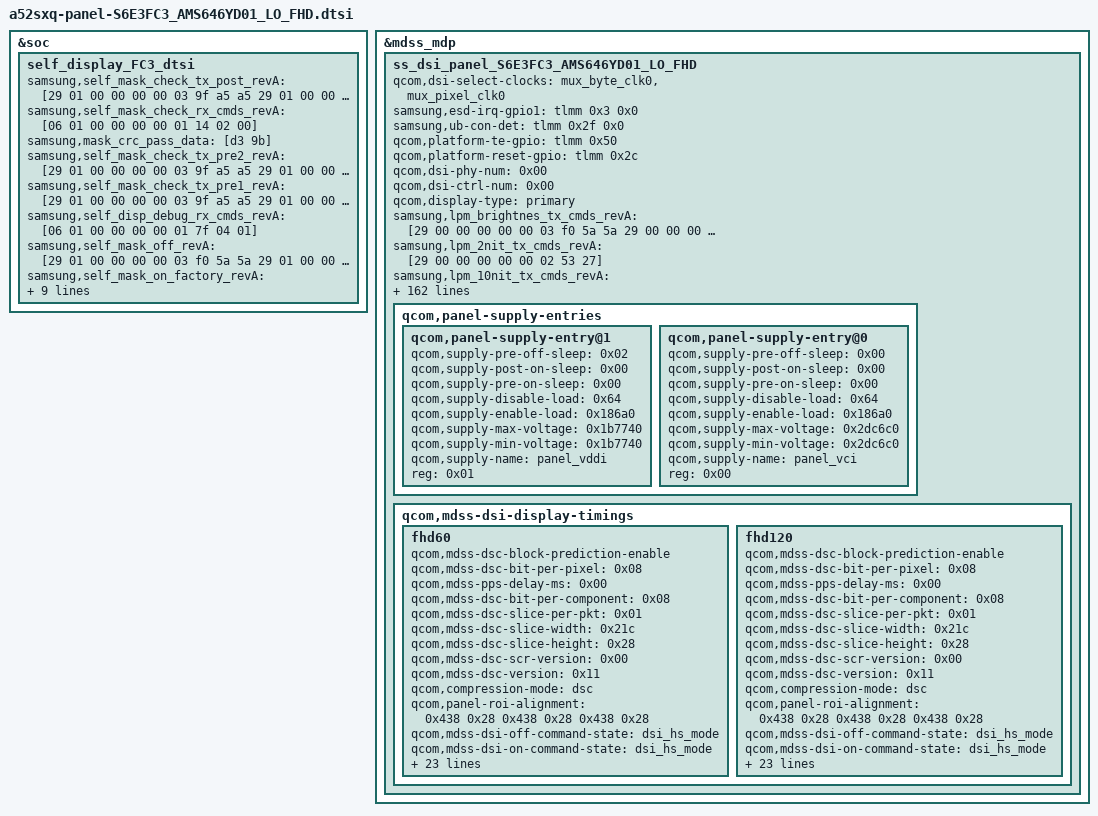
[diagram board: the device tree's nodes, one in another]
// SPDX-License-Identifier: GPL-2.0-only
/*
 * Samsung S6E3FC3 / AMS646YD01 panel node + its self-display (self mask) table.
 * GENERATED by tools/gen-dts.py from downstream-dt/a52sxq-r02.dts (the merged tree the
 * phone boots: yupik.dtb + overlay a52sxq_kor_single_w00_r02, used by hardware revisions
 * 2 and later, so 3 and 4 too). Values are byte-for-byte the phone's; only phandles were
 * turned into labels. Do not edit by hand; edit the generator.
 */

&soc {
	self_display_FC3_dtsi: self_display_FC3_dtsi {
		samsung,self_mask_check_tx_post_revA = [29 01 00 00 00 00 03 9f a5 a5 29 01 00 00 00 00 03 f0 5a 5a 29 01 00 00 00 00 03 fc 5a 5a 29 01 00 00 00 00 1a 7a 01 06 00 00 00 00 00 00 00 00 00 00 09 60 09 61 09 62 09 63 00 00 00 00 00 29 01 00 00 00 00 02 bf 00 29 01 00 00 00 00 03 fc a5 a5 29 01 00 00 00 00 03 f0 a5 a5 29 01 00 00 00 00 03 9f 5a 5a];
		samsung,self_mask_check_rx_cmds_revA = [06 01 00 00 00 00 01 14 02 00];
		samsung,mask_crc_pass_data = [d3 9b];
		samsung,self_mask_check_tx_pre2_revA = [29 01 00 00 00 00 03 9f a5 a5 29 01 00 00 00 00 03 f0 5a 5a 29 01 00 00 00 00 03 fc 5a 5a 29 01 00 00 00 00 02 75 00 29 01 00 00 22 00 1a 7a 01 06 00 00 00 00 00 00 00 00 00 00 01 f4 02 33 09 60 09 61 00 00 ff ff ff 29 01 00 00 00 00 03 fc a5 a5 29 01 00 00 00 00 03 f0 a5 a5 29 01 00 00 00 00 03 9f 5a 5a];
		samsung,self_mask_check_tx_pre1_revA = [29 01 00 00 00 00 03 9f a5 a5 29 01 00 00 00 00 03 f0 5a 5a 29 01 00 00 00 00 03 fc 5a 5a 29 01 00 00 00 00 04 b0 00 27 d8 29 01 00 00 00 00 02 d8 16 29 01 00 00 00 00 0a bf 01 07 00 00 00 10 00 00 00 29 01 00 00 11 00 02 7a 00 29 01 00 00 00 00 02 75 10 29 01 00 00 00 00 03 fc a5 a5 29 01 00 00 00 00 03 f0 a5 a5 29 01 00 00 00 00 03 9f 5a 5a];
		samsung,self_disp_debug_rx_cmds_revA = [06 01 00 00 00 00 01 7f 04 01];
		samsung,self_mask_off_revA = [29 01 00 00 00 00 03 f0 5a 5a 29 01 00 00 00 00 02 7a 00 29 01 00 00 00 00 03 f0 a5 a5];
		samsung,self_mask_on_factory_revA = [29 01 00 00 00 00 03 f0 5a 5a 29 01 00 00 00 00 17 7a 01 06 00 00 00 00 00 00 00 00 00 00 09 60 09 61 09 62 09 63 09 0c 29 01 00 00 00 00 03 f0 a5 a5];
		samsung,self_mask_on_revA = [29 01 00 00 00 00 03 f0 5a 5a 29 01 00 00 00 00 17 7a 01 06 00 00 00 00 00 00 00 00 00 00 00 00 00 95 07 9e 09 5f 09 0c 29 01 00 00 00 00 03 f0 a5 a5];
		samsung,self_mask_setting_post_revA = [29 01 00 00 00 00 02 75 00];
		samsung,self_mask_setting_pre_revA = [29 01 00 00 00 00 04 b0 00 10 f2 29 01 00 00 00 00 03 f2 26 f0 29 01 00 00 00 00 02 7a 00 29 01 00 00 00 00 02 75 10];
		samsung,support_self_display;
		label = "self_display_FC3_dtsi";
	};
};

&mdss_mdp {
	ss_dsi_panel_S6E3FC3_AMS646YD01_LO_FHD: ss_dsi_panel_S6E3FC3_AMS646YD01_LO_FHD {
		qcom,dsi-select-clocks = "mux_byte_clk0", "mux_pixel_clk0";
		samsung,esd-irq-gpio1 = <&tlmm 0x3 0x0>;
		samsung,ub-con-det = <&tlmm 0x2f 0x0>;
		qcom,platform-te-gpio = <&tlmm 0x50 0x0>;
		qcom,platform-reset-gpio = <&tlmm 0x2c 0x0>;
		qcom,dsi-phy-num = <0x00>;
		qcom,dsi-ctrl-num = <0x00>;
		qcom,display-type = "primary";
		samsung,lpm_brightnes_tx_cmds_revA = [29 00 00 00 00 00 03 f0 5a 5a 29 00 00 00 00 00 02 53 26 29 00 00 00 00 00 02 f7 0f 29 01 00 00 00 00 03 f0 a5 a5];
		samsung,lpm_2nit_tx_cmds_revA = [29 00 00 00 00 00 02 53 27];
		samsung,lpm_10nit_tx_cmds_revA = [29 00 00 00 00 00 02 53 26];
		samsung,lpm_30nit_tx_cmds_revA = [29 00 00 00 00 00 02 53 25];
		samsung,lpm_60nit_tx_cmds_revA = [29 00 00 00 00 00 02 53 24];
		samsung,lpm_off_tx_cmds_revA = [29 00 00 00 00 00 03 f0 5a 5a 29 00 00 00 00 00 04 b0 00 07 b5 29 00 00 00 00 00 04 b5 00 00 00 29 00 00 00 00 00 03 91 02 01 29 00 00 00 00 00 02 f7 0f 29 01 00 00 00 00 03 f0 a5 a5];
		samsung,lpm_off_tx_cmds_revI = [29 00 00 00 00 00 03 f0 5a 5a 29 00 00 00 00 00 04 b0 00 07 b5 29 00 00 00 00 00 04 b5 00 00 00 29 00 00 00 00 00 04 b0 01 88 cb 29 00 00 00 00 00 08 cb 45 0a 00 00 00 00 45 29 00 00 00 00 00 04 b0 01 c0 cb 29 00 00 00 00 00 08 cb 3d 00 00 00 18 03 3d 29 00 00 00 00 00 04 b0 00 10 f2 29 00 00 00 00 00 03 f2 26 f0 29 00 00 00 00 00 03 91 02 01 29 00 00 00 00 00 02 53 20 29 00 00 00 00 00 02 f7 0f 29 01 00 00 00 00 03 f0 a5 a5];
		samsung,lpm_on_tx_cmds_revA = <0x29000000 0x3f0 0x5a5a2900 0x00 0x3910101 0x29010000 0x253 0x26290000 0x02 0xf70f2901 0x00 0x3f0a5a5>;
		samsung,lpm_on_tx_cmds_revI = [29 00 00 00 00 00 03 f0 5a 5a 29 00 00 00 00 00 04 b0 00 4c f4 29 00 00 00 00 00 02 f4 28 29 00 00 00 00 00 03 91 01 01 29 00 00 00 00 00 02 53 27 29 00 00 00 00 00 04 b0 01 88 cb 29 00 00 00 00 00 08 cb 40 0a 00 00 00 00 40 29 00 00 00 00 00 04 b0 01 c0 cb 29 00 00 00 00 00 08 cb 38 00 00 00 18 03 38 29 00 00 00 00 00 04 b0 00 10 f2 29 00 00 00 00 00 03 f2 24 a4 29 01 00 00 00 00 02 f7 0f 29 01 00 00 00 00 03 f0 a5 a5];
		samsung,self_grid_off_revA = [29 01 00 00 11 00 03 f0 5a 5a 29 00 00 00 00 00 03 bf 00 00 29 01 00 00 00 00 03 f0 a5 a5];
		samsung,self_grid_on_revA = [29 00 00 00 00 00 03 f0 5a 5a 29 00 00 00 00 00 03 bf 01 00 29 01 00 00 11 00 03 f0 a5 a5];
		samsung,fd_off_tx_cmds_revA = [29 00 00 00 00 00 03 f0 5a 5a 29 00 00 00 00 00 04 b0 00 0a b5 29 00 00 00 00 00 03 b5 80 40 29 01 00 00 00 00 03 f0 a5 a5];
		samsung,fd_on_tx_cmds_revA = [29 00 00 00 00 00 03 f0 5a 5a 29 00 00 00 00 00 04 b0 00 0a b5 29 00 00 00 00 00 03 b5 40 40 29 01 00 00 00 00 03 f0 a5 a5];
		samsung,dynamic_mipi_clk_sel_table = <0x01 0x01 0x00 0x00 0x00 0x01 0x02 0x00 0x00 0x01 0x01 0x03 0x00 0x00 0x00 0x01 0x04 0x00 0x00 0x00 0x02 0x0b 0x2942 0x2a56 0x00 0x02 0x0c 0x25be 0x261a 0x01 0x02 0x0c 0x261b 0x26d2 0x00 0x02 0x0d 0x48a 0x4a3 0x01 0x02 0x0d 0x4a4 0x5e9 0x00 0x02 0x0e 0x601 0x6ca 0x00 0x02 0x0f 0x1105 0x116a 0x00 0x02 0x11 0x8bd 0x926 0x01 0x02 0x11 0x927 0xa03 0x00 0x02 0x12 0xb79 0xc0f 0x00 0x02 0x12 0xc10 0xc10 0x01 0x03 0x5b 0x00 0x257 0x00 0x03 0x5c 0x258 0x329 0x01 0x03 0x5c 0x32a 0x4af 0x00 0x03 0x5d 0x4b0 0x4fa 0x01 0x03 0x5d 0x4fb 0x79d 0x00 0x03 0x5e 0x79e 0x95f 0x00 0x03 0x5f 0x960 0xa59 0x00 0x03 0x61 0xabe 0xba8 0x01 0x03 0x61 0xba9 0xd79 0x00 0x03 0x62 0xd7a 0xebe 0x00 0x03 0x62 0xebf 0xed7 0x01 0x03 0x66 0x1392 0x143b 0x00 0x03 0x67 0x143c 0x149f 0x00 0x03 0x68 0x14a0 0x1503 0x00 0x03 0x6b 0x1662 0x16d9 0x00 0x03 0x6c 0x16da 0x176f 0x00 0x03 0x6d 0x1770 0x1805 0x00 0x03 0x6e 0x1806 0x191d 0x00 0x03 0x6e 0x191e 0x1931 0x01 0x03 0x6f 0x1932 0x19c7 0x00 0x03 0x73 0x1f68 0x2039 0x01 0x03 0x73 0x203a 0x21f1 0x00 0x03 0x74 0x21f2 0x234f 0x00 0x03 0x76 0x23fa 0x25bb 0x00 0x03 0x77 0x25bc 0x2629 0x00 0x03 0x78 0x262a 0x268d 0x01 0x03 0x7a 0x26c0 0x2877 0x00 0x03 0x7c 0x8d68 0x8dfd 0x00 0x03 0x80 0x9376 0x9564 0x00 0x03 0x80 0x9565 0x9569 0x01 0x03 0x81 0x956a 0x96f9 0x00 0x03 0x82 0x96fa 0x98a2 0x00 0x03 0x82 0x98a3 0x9992 0x01 0x03 0x82 0x9993 0x9ae1 0x00 0x03 0x83 0x9ae2 0x9b3b 0x01 0x03 0x83 0x9b3c 0x9fb4 0x00 0x03 0x83 0x9fb5 0xa0a4 0x01 0x03 0x83 0xa0a5 0xa275 0x00 0x03 0x84 0xa276 0xa46f 0x00 0x03 0x84 0xa470 0xa55f 0x01 0x03 0x84 0xa560 0xa9d8 0x00 0x03 0x84 0xa9d9 0xaa45 0x01 0x03 0x8a 0xd7c8 0xd94e 0x00 0x03 0x8a 0xd94f 0xda3e 0x01 0x03 0x8a 0xda3f 0xdda3 0x00 0x03 0x9c 0x10384 0x10707 0x00 0x03 0xa1 0x10bea 0x10d47 0x00 0x04 0x33 0x00 0x00 0x00 0x04 0x34 0x00 0x00 0x00 0x04 0x35 0x00 0x00 0x01 0x04 0x36 0x00 0x00 0x01 0x04 0x37 0x00 0x00 0x02 0x04 0x38 0x00 0x00 0x00 0x05 0x3d 0x00 0x00 0x00 0x05 0x3e 0x00 0x00 0x00 0x05 0x47 0x00 0x00 0x00 0x07 0x104 0x2a6e8 0x2ba5c 0x00 0x07 0x107 0x2d2a8 0x2e1d0 0x00 0x07 0x107 0x2e1d1 0x2ecc0 0x01 0x07 0x107 0x2ecc1 0x2edec 0x02 0x07 0x11b 0x25030 0x27344 0x00 0x07 0x146 0x1e208 0x1fd4c 0x00>;
		samsung,dynamic_mipi_clk_timing_table = <0x420abd00 0x42fee100 0x430e2340>;
		samsung,dyn_mipi_clk_ffc_cmds_revA = <0x29000000 0x4b0 0x2ac529 0x00 0x5c50d 0x10804529 0x00 0x4b000 0x2ec52900 0x00 0x3c553c7 0x29000000 0x4b0 0x2ac529 0x00 0x5c50d 0x10804529 0x00 0x4b000 0x2ec52900 0x00 0x3c55296 0x29000000 0x4b0 0x2ac529 0x00 0x5c50d 0x10804529 0x00 0x4b000 0x2ec52900 0x00 0x3c55283>;
		samsung,ffc_tx_cmds_revA = [29 00 00 00 00 00 03 f0 5a 5a 29 00 00 00 00 00 03 fc 5a 5a 29 00 00 00 00 00 04 b0 00 2a c5 29 00 00 00 00 00 05 c5 0d 10 80 45 29 00 00 00 00 00 04 b0 00 2e c5 29 00 00 00 00 00 03 c5 53 c7 29 00 00 00 00 00 02 f7 0f 29 00 00 00 00 00 03 fc a5 a5 29 00 00 00 00 00 03 f0 a5 a5];
		samsung,support_dynamic_mipi_clk;
		samsung,hmt_disable_tx_cmds_revA = [29 00 00 00 00 00 03 f0 5a 5a 29 00 00 00 00 00 04 b0 00 0b cb 29 00 00 00 00 00 02 cb 11 29 00 00 00 00 00 04 b0 00 1f cb 29 00 00 00 00 00 02 cb 11 29 00 00 00 00 00 04 b0 00 39 cb 29 00 00 00 00 00 02 cb 7f 29 00 00 00 00 00 04 b0 00 60 cb 29 00 00 00 00 00 02 cb 06 29 00 00 00 00 00 04 b0 00 ab cb 29 00 00 00 00 00 02 cb 00 29 00 00 00 00 00 04 b0 00 e0 cb 29 00 00 00 00 00 02 cb 06 29 00 00 00 00 00 04 b0 01 2b cb 29 00 00 00 00 00 02 cb 00 29 00 00 00 00 00 04 b0 01 ab cb 29 00 00 00 00 00 02 cb 00 29 00 00 00 00 00 04 b0 00 06 f2 29 00 00 00 00 00 02 f2 0c 29 00 00 00 00 00 04 b0 02 2c 65 29 00 00 00 00 00 02 65 11 29 00 00 00 00 00 04 b0 01 d4 65 29 00 00 00 00 00 03 65 09 70 29 00 00 00 00 00 04 b0 01 ee 65 29 00 00 00 00 00 05 65 01 84 01 84 29 00 00 00 0a 00 02 f7 0f 29 00 00 00 00 00 03 f0 a5 a5];
		samsung,hmt_enable_tx_cmds_revA = [29 00 00 00 00 00 03 f0 5a 5a 29 00 00 00 00 00 03 60 00 00 29 00 00 00 00 00 04 b0 00 28 68 29 00 00 00 00 00 02 68 22 29 00 00 00 00 00 04 b0 00 0d f2 29 00 00 00 00 00 02 f2 14 29 00 00 00 00 00 04 b0 02 2c 65 29 00 00 00 00 00 02 65 10 29 00 00 00 00 00 04 b0 01 d4 65 29 00 00 00 00 00 03 65 12 d8 29 00 00 00 00 00 04 b0 01 ee 65 29 00 00 00 00 00 05 65 0f 6a 0f 6a 29 00 00 00 11 00 02 f7 0f 29 00 00 00 00 00 04 b0 00 0b cb 29 00 00 00 00 00 02 cb 12 29 00 00 00 00 00 04 b0 00 1f cb 29 00 00 00 00 00 02 cb 12 29 00 00 00 00 00 04 b0 00 39 cb 29 00 00 00 00 00 02 cb bf 29 00 00 00 00 00 04 b0 00 60 cb 29 00 00 00 00 00 02 cb 0e 29 00 00 00 00 00 04 b0 00 ab cb 29 00 00 00 00 00 02 cb 17 29 00 00 00 00 00 04 b0 00 e0 cb 29 00 00 00 00 00 02 cb 0e 29 00 00 00 00 00 04 b0 01 2b cb 29 00 00 00 00 00 02 cb 17 29 00 00 00 00 00 04 b0 01 ab cb 29 00 00 00 00 00 02 cb 17 29 00 00 00 0a 00 02 f7 0f 29 00 00 00 00 00 03 51 03 ff 29 00 00 00 00 00 03 f0 a5 a5];
		samsung,gamma_mode2_hmt_tx_cmds_revA = [29 00 00 00 00 00 03 51 03 ff 29 00 00 00 00 00 02 f7 0f];
		samsung,hmt_candela_map_table_revA = <0x00 0x00 0x00 0x10c 0x14 0x01 0x01 0x01 0x10f 0x14 0x02 0x02 0x02 0x112 0x15 0x03 0x03 0x03 0x115 0x15 0x04 0x04 0x04 0x118 0x15 0x05 0x05 0x05 0x11b 0x16 0x06 0x06 0x06 0x11e 0x16 0x07 0x07 0x07 0x121 0x16 0x08 0x08 0x08 0x124 0x17 0x09 0x09 0x09 0x127 0x17 0x0a 0x0a 0x0a 0x12a 0x17 0x0b 0x0b 0x0b 0x12d 0x18 0x0c 0x0c 0x0c 0x130 0x18 0x0d 0x0d 0x0d 0x132 0x18 0x0e 0x0e 0x0e 0x135 0x19 0x0f 0x0f 0x0f 0x138 0x19 0x10 0x10 0x10 0x13b 0x19 0x11 0x11 0x11 0x13e 0x1a 0x12 0x12 0x12 0x141 0x1a 0x13 0x13 0x13 0x144 0x1a 0x14 0x14 0x14 0x147 0x1b 0x15 0x15 0x15 0x14a 0x1b 0x16 0x16 0x16 0x14d 0x1b 0x17 0x17 0x17 0x150 0x1c 0x18 0x18 0x18 0x153 0x1c 0x19 0x19 0x19 0x156 0x1c 0x1a 0x1a 0x1a 0x159 0x1d 0x1b 0x1b 0x1b 0x15c 0x1d 0x1c 0x1c 0x1c 0x15f 0x1d 0x1d 0x1d 0x1d 0x162 0x1e 0x1e 0x1e 0x1e 0x165 0x1e 0x1f 0x1f 0x1f 0x168 0x1e 0x20 0x20 0x20 0x16b 0x1f 0x21 0x21 0x21 0x16e 0x1f 0x22 0x22 0x22 0x171 0x1f 0x23 0x23 0x23 0x174 0x20 0x24 0x24 0x24 0x177 0x20 0x25 0x25 0x25 0x17a 0x20 0x26 0x26 0x26 0x17c 0x21 0x27 0x27 0x27 0x17f 0x21 0x28 0x28 0x28 0x182 0x21 0x29 0x29 0x29 0x185 0x22 0x2a 0x2a 0x2a 0x188 0x22 0x2b 0x2b 0x2b 0x18b 0x22 0x2c 0x2c 0x2c 0x18e 0x23 0x2d 0x2d 0x2d 0x191 0x23 0x2e 0x2e 0x2e 0x194 0x23 0x2f 0x2f 0x2f 0x197 0x24 0x30 0x30 0x30 0x19a 0x24 0x31 0x31 0x31 0x19d 0x24 0x32 0x32 0x32 0x1a0 0x25 0x33 0x33 0x33 0x1a3 0x25 0x34 0x34 0x34 0x1a6 0x25 0x35 0x35 0x35 0x1a9 0x26 0x36 0x36 0x36 0x1ac 0x26 0x37 0x37 0x37 0x1af 0x26 0x38 0x38 0x38 0x1b2 0x27 0x39 0x39 0x39 0x1b5 0x27 0x3a 0x3a 0x3a 0x1b8 0x27 0x3b 0x3b 0x3b 0x1bb 0x28 0x3c 0x3c 0x3c 0x1be 0x28 0x3d 0x3d 0x3d 0x1c1 0x28 0x3e 0x3e 0x3e 0x1c4 0x29 0x3f 0x3f 0x3f 0x1c7 0x29 0x40 0x40 0x40 0x1c9 0x29 0x41 0x41 0x41 0x1cc 0x2a 0x42 0x42 0x42 0x1cf 0x2a 0x43 0x43 0x43 0x1d2 0x2a 0x44 0x44 0x44 0x1d5 0x2b 0x45 0x45 0x45 0x1d8 0x2b 0x46 0x46 0x46 0x1db 0x2b 0x47 0x47 0x47 0x1de 0x2c 0x48 0x48 0x48 0x1e1 0x2c 0x49 0x49 0x49 0x1e4 0x2c 0x4a 0x4a 0x4a 0x1e7 0x2d 0x4b 0x4b 0x4b 0x1ea 0x2d 0x4c 0x4c 0x4c 0x1ed 0x2d 0x4d 0x4d 0x4d 0x1f0 0x2e 0x4e 0x4e 0x4e 0x1f3 0x2e 0x4f 0x4f 0x4f 0x1f6 0x2e 0x50 0x50 0x50 0x1f9 0x2f 0x51 0x51 0x51 0x1fc 0x2f 0x52 0x52 0x52 0x1ff 0x2f 0x53 0x53 0x53 0x202 0x30 0x54 0x54 0x54 0x205 0x30 0x55 0x55 0x55 0x208 0x30 0x56 0x56 0x56 0x20b 0x31 0x57 0x57 0x57 0x20e 0x31 0x58 0x58 0x58 0x211 0x31 0x59 0x59 0x59 0x213 0x32 0x5a 0x5a 0x5a 0x216 0x32 0x5b 0x5b 0x5b 0x219 0x32 0x5c 0x5c 0x5c 0x21c 0x33 0x5d 0x5d 0x5d 0x21f 0x33 0x5e 0x5e 0x5e 0x222 0x33 0x5f 0x5f 0x5f 0x225 0x34 0x60 0x60 0x60 0x228 0x34 0x61 0x61 0x61 0x22b 0x34 0x62 0x62 0x62 0x22e 0x35 0x63 0x63 0x63 0x231 0x35 0x64 0x64 0x64 0x234 0x35 0x65 0x65 0x65 0x237 0x36 0x66 0x66 0x66 0x23a 0x36 0x67 0x67 0x67 0x23d 0x36 0x68 0x68 0x68 0x240 0x37 0x69 0x69 0x69 0x243 0x37 0x6a 0x6a 0x6a 0x246 0x37 0x6b 0x6b 0x6b 0x249 0x38 0x6c 0x6c 0x6c 0x24c 0x38 0x6d 0x6d 0x6d 0x24f 0x38 0x6e 0x6e 0x6e 0x252 0x39 0x6f 0x6f 0x6f 0x255 0x39 0x70 0x70 0x70 0x258 0x39 0x71 0x71 0x71 0x25b 0x3a 0x72 0x72 0x72 0x25e 0x3a 0x73 0x73 0x73 0x260 0x3a 0x74 0x74 0x74 0x263 0x3b 0x75 0x75 0x75 0x266 0x3b 0x76 0x76 0x76 0x269 0x3b 0x77 0x77 0x77 0x26c 0x3c 0x78 0x78 0x78 0x26f 0x3c 0x79 0x79 0x79 0x272 0x3c 0x7a 0x7a 0x7a 0x275 0x3d 0x7b 0x7b 0x7b 0x278 0x3d 0x7c 0x7c 0x7c 0x27b 0x3d 0x7d 0x7d 0x7d 0x27e 0x3e 0x7e 0x7e 0x7e 0x281 0x3e 0x7f 0x7f 0x7f 0x284 0x3e 0x80 0x80 0x80 0x287 0x3f 0x81 0x81 0x81 0x28a 0x3f 0x82 0x82 0x82 0x28d 0x3f 0x83 0x83 0x83 0x290 0x40 0x84 0x84 0x84 0x293 0x40 0x85 0x85 0x85 0x296 0x40 0x86 0x86 0x86 0x299 0x41 0x87 0x87 0x87 0x29c 0x41 0x88 0x88 0x88 0x29f 0x41 0x89 0x89 0x89 0x2a2 0x42 0x8a 0x8a 0x8a 0x2a5 0x42 0x8b 0x8b 0x8b 0x2a8 0x42 0x8c 0x8c 0x8c 0x2aa 0x43 0x8d 0x8d 0x8d 0x2ad 0x43 0x8e 0x8e 0x8e 0x2b0 0x43 0x8f 0x8f 0x8f 0x2b3 0x44 0x90 0x90 0x90 0x2b6 0x44 0x91 0x91 0x91 0x2b9 0x44 0x92 0x92 0x92 0x2bc 0x45 0x93 0x93 0x93 0x2bf 0x45 0x94 0x94 0x94 0x2c2 0x45 0x95 0x95 0x95 0x2c5 0x46 0x96 0x96 0x96 0x2c8 0x46 0x97 0x97 0x97 0x2cb 0x46 0x98 0x98 0x98 0x2ce 0x47 0x99 0x99 0x99 0x2d1 0x47 0x9a 0x9a 0x9a 0x2d4 0x47 0x9b 0x9b 0x9b 0x2d7 0x48 0x9c 0x9c 0x9c 0x2da 0x48 0x9d 0x9d 0x9d 0x2dd 0x48 0x9e 0x9e 0x9e 0x2e0 0x49 0x9f 0x9f 0x9f 0x2e3 0x49 0xa0 0xa0 0xa0 0x2e6 0x49 0xa1 0xa1 0xa1 0x2e9 0x4a 0xa2 0xa2 0xa2 0x2ec 0x4a 0xa3 0xa3 0xa3 0x2ef 0x4a 0xa4 0xa4 0xa4 0x2f2 0x4b 0xa5 0xa5 0xa5 0x2f5 0x4b 0xa6 0xa6 0xa6 0x2f7 0x4b 0xa7 0xa7 0xa7 0x2fa 0x4c 0xa8 0xa8 0xa8 0x2fd 0x4c 0xa9 0xa9 0xa9 0x300 0x4c 0xaa 0xaa 0xaa 0x303 0x4d 0xab 0xab 0xab 0x306 0x4d 0xac 0xac 0xac 0x309 0x4d 0xad 0xad 0xad 0x30c 0x4e 0xae 0xae 0xae 0x30f 0x4e 0xaf 0xaf 0xaf 0x312 0x4e 0xb0 0xb0 0xb0 0x315 0x4f 0xb1 0xb1 0xb1 0x318 0x4f 0xb2 0xb2 0xb2 0x31b 0x4f 0xb3 0xb3 0xb3 0x31e 0x50 0xb4 0xb4 0xb4 0x321 0x50 0xb5 0xb5 0xb5 0x324 0x50 0xb6 0xb6 0xb6 0x327 0x51 0xb7 0xb7 0xb7 0x32a 0x51 0xb8 0xb8 0xb8 0x32d 0x51 0xb9 0xb9 0xb9 0x330 0x52 0xba 0xba 0xba 0x333 0x52 0xbb 0xbb 0xbb 0x336 0x52 0xbc 0xbc 0xbc 0x339 0x53 0xbd 0xbd 0xbd 0x33c 0x53 0xbe 0xbe 0xbe 0x33f 0x53 0xbf 0xbf 0xbf 0x341 0x54 0xc0 0xc0 0xc0 0x344 0x54 0xc1 0xc1 0xc1 0x347 0x54 0xc2 0xc2 0xc2 0x34a 0x55 0xc3 0xc3 0xc3 0x34d 0x55 0xc4 0xc4 0xc4 0x350 0x55 0xc5 0xc5 0xc5 0x353 0x56 0xc6 0xc6 0xc6 0x356 0x56 0xc7 0xc7 0xc7 0x359 0x56 0xc8 0xc8 0xc8 0x35c 0x57 0xc9 0xc9 0xc9 0x35f 0x57 0xca 0xca 0xca 0x362 0x57 0xcb 0xcb 0xcb 0x365 0x58 0xcc 0xcc 0xcc 0x368 0x58 0xcd 0xcd 0xcd 0x36b 0x58 0xce 0xce 0xce 0x36e 0x59 0xcf 0xcf 0xcf 0x371 0x59 0xd0 0xd0 0xd0 0x374 0x59 0xd1 0xd1 0xd1 0x377 0x5a 0xd2 0xd2 0xd2 0x37a 0x5a 0xd3 0xd3 0xd3 0x37d 0x5a 0xd4 0xd4 0xd4 0x380 0x5b 0xd5 0xd5 0xd5 0x383 0x5b 0xd6 0xd6 0xd6 0x386 0x5b 0xd7 0xd7 0xd7 0x389 0x5c 0xd8 0xd8 0xd8 0x38c 0x5c 0xd9 0xd9 0xd9 0x38e 0x5c 0xda 0xda 0xda 0x391 0x5d 0xdb 0xdb 0xdb 0x394 0x5d 0xdc 0xdc 0xdc 0x397 0x5d 0xdd 0xdd 0xdd 0x39a 0x5e 0xde 0xde 0xde 0x39d 0x5e 0xdf 0xdf 0xdf 0x3a0 0x5e 0xe0 0xe0 0xe0 0x3a3 0x5f 0xe1 0xe1 0xe1 0x3a6 0x5f 0xe2 0xe2 0xe2 0x3a9 0x5f 0xe3 0xe3 0xe3 0x3ac 0x60 0xe4 0xe4 0xe4 0x3af 0x60 0xe5 0xe5 0xe5 0x3b2 0x60 0xe6 0xe6 0xe6 0x3b5 0x61 0xe7 0xe7 0xe7 0x3b8 0x61 0xe8 0xe8 0xe8 0x3bb 0x61 0xe9 0xe9 0xe9 0x3be 0x62 0xea 0xea 0xea 0x3c1 0x62 0xeb 0xeb 0xeb 0x3c4 0x62 0xec 0xec 0xec 0x3c7 0x63 0xed 0xed 0xed 0x3ca 0x63 0xee 0xee 0xee 0x3cd 0x63 0xef 0xef 0xef 0x3d0 0x64 0xf0 0xf0 0xf0 0x3d3 0x64 0xf1 0xf1 0xf1 0x3d6 0x64 0xf2 0xf2 0xf2 0x3d8 0x65 0xf3 0xf3 0xf3 0x3db 0x65 0xf4 0xf4 0xf4 0x3de 0x65 0xf5 0xf5 0xf5 0x3e1 0x66 0xf6 0xf6 0xf6 0x3e4 0x66 0xf7 0xf7 0xf7 0x3e7 0x66 0xf8 0xf8 0xf8 0x3ea 0x67 0xf9 0xf9 0xf9 0x3ed 0x67 0xfa 0xfa 0xfa 0x3f0 0x67 0xfb 0xfb 0xfb 0x3f3 0x68 0xfc 0xfc 0xfc 0x3f6 0x68 0xfd 0xfd 0xfd 0x3f9 0x68 0xfe 0xfe 0xfe 0x3fc 0x69 0xff 0xff 0xff 0x3ff 0x69>;
		samsung,support_hmt;
		samsung,aod_candela_map_table_revA = <0x00 0x00 0x0b 0x1b 0x02 0x01 0x0c 0x1f 0x1a 0x0a 0x02 0x20 0x36 0x19 0x1e 0x03 0x37 0xff 0x18 0x3c>;
		samsung,hbm_candela_map_table_revA = <0x00 0x100 0x100 0x00 0x1a9 0x01 0x101 0x101 0x03 0x1aa 0x02 0x102 0x102 0x06 0x1ac 0x03 0x103 0x103 0x09 0x1ae 0x04 0x104 0x104 0x0c 0x1b0 0x05 0x105 0x105 0x0f 0x1b1 0x06 0x106 0x106 0x12 0x1b3 0x07 0x107 0x107 0x15 0x1b4 0x08 0x108 0x108 0x18 0x1b6 0x09 0x109 0x109 0x1b 0x1b8 0x0a 0x10a 0x10a 0x1e 0x1b9 0x0b 0x10b 0x10b 0x21 0x1bb 0x0c 0x10c 0x10c 0x24 0x1bc 0x0d 0x10d 0x10d 0x27 0x1be 0x0e 0x10e 0x10e 0x2a 0x1c0 0x0f 0x10f 0x10f 0x2d 0x1c2 0x10 0x110 0x110 0x30 0x1c3 0x11 0x111 0x111 0x33 0x1c5 0x12 0x112 0x112 0x36 0x1c6 0x13 0x113 0x113 0x39 0x1c8 0x14 0x114 0x114 0x3c 0x1ca 0x15 0x115 0x115 0x3f 0x1cb 0x16 0x116 0x116 0x42 0x1cd 0x17 0x117 0x117 0x45 0x1ce 0x18 0x118 0x118 0x48 0x1d0 0x19 0x119 0x119 0x4b 0x1d2 0x1a 0x11a 0x11a 0x4e 0x1d4 0x1b 0x11b 0x11b 0x51 0x1d5 0x1c 0x11c 0x11c 0x54 0x1d7 0x1d 0x11d 0x11d 0x56 0x1d8 0x1e 0x11e 0x11e 0x58 0x1da 0x1f 0x11f 0x11f 0x5a 0x1dc 0x20 0x120 0x120 0x5c 0x1dd 0x21 0x121 0x121 0x5e 0x1df 0x22 0x122 0x122 0x60 0x1e0 0x23 0x123 0x123 0x62 0x1e2 0x24 0x124 0x124 0x64 0x1e4 0x25 0x125 0x125 0x66 0x1e5 0x26 0x126 0x126 0x68 0x1e7 0x27 0x127 0x127 0x6a 0x1e8 0x28 0x128 0x128 0x6c 0x1ea 0x29 0x129 0x129 0x6e 0x1ec 0x2a 0x12a 0x12a 0x70 0x1ee 0x2b 0x12b 0x12b 0x72 0x1ef 0x2c 0x12c 0x12c 0x74 0x1f1 0x2d 0x12d 0x12d 0x76 0x1f2 0x2e 0x12e 0x12e 0x78 0x1f4 0x2f 0x12f 0x12f 0x7a 0x1f6 0x30 0x130 0x130 0x7c 0x1f7 0x31 0x131 0x131 0x7e 0x1f9 0x32 0x132 0x132 0x80 0x1fa 0x33 0x133 0x133 0x82 0x1fc 0x34 0x134 0x134 0x84 0x1fe 0x35 0x135 0x135 0x86 0x200 0x36 0x136 0x136 0x88 0x201 0x37 0x137 0x137 0x8a 0x203 0x38 0x138 0x138 0x8c 0x204 0x39 0x139 0x139 0x8e 0x206 0x3a 0x13a 0x13a 0x90 0x208 0x3b 0x13b 0x13b 0x92 0x209 0x3c 0x13c 0x13c 0x94 0x20b 0x3d 0x13d 0x13d 0x96 0x20c 0x3e 0x13e 0x13e 0x98 0x20e 0x3f 0x13f 0x13f 0x9a 0x210 0x40 0x140 0x140 0x9c 0x211 0x41 0x141 0x141 0x9e 0x213 0x42 0x142 0x142 0xa0 0x215 0x43 0x143 0x143 0xa2 0x216 0x44 0x144 0x144 0xa4 0x218 0x45 0x145 0x145 0xa6 0x21a 0x46 0x146 0x146 0xa8 0x21b 0x47 0x147 0x147 0xaa 0x21d 0x48 0x148 0x148 0xac 0x21e 0x49 0x149 0x149 0xae 0x220 0x4a 0x14a 0x14a 0xb0 0x222 0x4b 0x14b 0x14b 0xb2 0x223 0x4c 0x14c 0x14c 0xb6 0x225 0x4d 0x14d 0x14d 0xba 0x226 0x4e 0x14e 0x14e 0xbe 0x228 0x4f 0x14f 0x14f 0xc2 0x22a 0x50 0x150 0x150 0xc6 0x22b 0x51 0x151 0x151 0xcb 0x22d 0x52 0x152 0x152 0xd0 0x22f 0x53 0x153 0x153 0xd5 0x230 0x54 0x154 0x154 0xda 0x232 0x55 0x155 0x155 0xdf 0x234 0x56 0x156 0x156 0xe4 0x235 0x57 0x157 0x157 0xe9 0x237 0x58 0x158 0x158 0xee 0x238 0x59 0x159 0x159 0xf3 0x23a 0x5a 0x15a 0x15a 0xf8 0x23c 0x5b 0x15b 0x15b 0xfd 0x23d 0x5c 0x15c 0x15c 0x102 0x23f 0x5d 0x15d 0x15d 0x107 0x241 0x5e 0x15e 0x15e 0x10c 0x242 0x5f 0x15f 0x15f 0x111 0x244 0x60 0x160 0x160 0x116 0x246 0x61 0x161 0x161 0x11b 0x247 0x62 0x162 0x162 0x120 0x249 0x63 0x163 0x163 0x125 0x24a 0x64 0x164 0x164 0x12a 0x24c 0x65 0x165 0x165 0x12f 0x24e 0x66 0x166 0x166 0x134 0x24f 0x67 0x167 0x167 0x139 0x251 0x68 0x168 0x168 0x13e 0x253 0x69 0x169 0x169 0x143 0x254 0x6a 0x16a 0x16a 0x148 0x256 0x6b 0x16b 0x16b 0x14d 0x257 0x6c 0x16c 0x16c 0x152 0x259 0x6d 0x16d 0x16d 0x157 0x25b 0x6e 0x16e 0x16e 0x15c 0x25c 0x6f 0x16f 0x16f 0x161 0x25e 0x70 0x170 0x170 0x166 0x260 0x71 0x171 0x171 0x16b 0x261 0x72 0x172 0x172 0x170 0x263 0x73 0x173 0x173 0x175 0x264 0x74 0x174 0x174 0x17a 0x266 0x75 0x175 0x175 0x17f 0x268 0x76 0x176 0x176 0x184 0x269 0x77 0x177 0x177 0x189 0x26b 0x78 0x178 0x178 0x18e 0x26d 0x79 0x179 0x179 0x193 0x26e 0x7a 0x17a 0x17a 0x198 0x270 0x7b 0x17b 0x17b 0x19d 0x272 0x7c 0x17c 0x17c 0x1a2 0x273 0x7d 0x17d 0x17d 0x1a7 0x275 0x7e 0x17e 0x17e 0x1ac 0x276 0x7f 0x17f 0x17f 0x1b1 0x278 0x80 0x180 0x180 0x1b6 0x27a 0x81 0x181 0x181 0x1bb 0x27b 0x82 0x182 0x182 0x1c0 0x27d 0x83 0x183 0x183 0x1c5 0x27f 0x84 0x184 0x184 0x1ca 0x280 0x85 0x185 0x185 0x1cf 0x282 0x86 0x186 0x186 0x1d4 0x283 0x87 0x187 0x187 0x1d9 0x285 0x88 0x188 0x188 0x1de 0x287 0x89 0x189 0x189 0x1e3 0x288 0x8a 0x18a 0x18a 0x1e8 0x28a 0x8b 0x18b 0x18b 0x1ed 0x28c 0x8c 0x18c 0x18c 0x1f2 0x28d 0x8d 0x18d 0x18d 0x1f7 0x28f 0x8e 0x18e 0x18e 0x1fc 0x291 0x8f 0x18f 0x18f 0x201 0x292 0x90 0x190 0x190 0x206 0x294 0x91 0x191 0x191 0x20b 0x295 0x92 0x192 0x192 0x210 0x297 0x93 0x193 0x193 0x215 0x299 0x94 0x194 0x194 0x21a 0x29a 0x95 0x195 0x195 0x21f 0x29c 0x96 0x196 0x196 0x224 0x29e 0x97 0x197 0x197 0x229 0x29f 0x98 0x198 0x198 0x22e 0x2a1 0x99 0x199 0x199 0x233 0x2a3 0x9a 0x19a 0x19a 0x238 0x2a4 0x9b 0x19b 0x19b 0x23d 0x2a6 0x9c 0x19c 0x19c 0x242 0x2a7 0x9d 0x19d 0x19d 0x247 0x2a9 0x9e 0x19e 0x19e 0x24d 0x2ab 0x9f 0x19f 0x19f 0x253 0x2ac 0xa0 0x1a0 0x1a0 0x259 0x2ae 0xa1 0x1a1 0x1a1 0x25f 0x2af 0xa2 0x1a2 0x1a2 0x265 0x2b1 0xa3 0x1a3 0x1a3 0x26b 0x2b3 0xa4 0x1a4 0x1a4 0x271 0x2b4 0xa5 0x1a5 0x1a5 0x277 0x2b6 0xa6 0x1a6 0x1a6 0x27d 0x2b8 0xa7 0x1a7 0x1a7 0x283 0x2b9 0xa8 0x1a8 0x1a8 0x289 0x2bb 0xa9 0x1a9 0x1a9 0x28f 0x2bd 0xaa 0x1aa 0x1aa 0x295 0x2be 0xab 0x1ab 0x1ab 0x29b 0x2c0 0xac 0x1ac 0x1ac 0x2a1 0x2c1 0xad 0x1ad 0x1ad 0x2a7 0x2c3 0xae 0x1ae 0x1ae 0x2ad 0x2c5 0xaf 0x1af 0x1af 0x2b3 0x2c6 0xb0 0x1b0 0x1b0 0x2b9 0x2c8 0xb1 0x1b1 0x1b1 0x2bf 0x2c9 0xb2 0x1b2 0x1b2 0x2c5 0x2cb 0xb3 0x1b3 0x1b3 0x2cb 0x2cd 0xb4 0x1b4 0x1b4 0x2d1 0x2cf 0xb5 0x1b5 0x1b5 0x2d7 0x2d0 0xb6 0x1b6 0x1b6 0x2dd 0x2d2 0xb7 0x1b7 0x1b7 0x2e3 0x2d3 0xb8 0x1b8 0x1b8 0x2e9 0x2d5 0xb9 0x1b9 0x1b9 0x2ef 0x2d7 0xba 0x1ba 0x1ba 0x2f5 0x2d8 0xbb 0x1bb 0x1bb 0x2fb 0x2da 0xbc 0x1bc 0x1bc 0x301 0x2db 0xbd 0x1bd 0x1bd 0x307 0x2dd 0xbe 0x1be 0x1be 0x30d 0x2df 0xbf 0x1bf 0x1bf 0x313 0x2e1 0xc0 0x1c0 0x1c0 0x319 0x2e2 0xc1 0x1c1 0x1c1 0x31f 0x2e4 0xc2 0x1c2 0x1c2 0x325 0x2e5 0xc3 0x1c3 0x1c3 0x32b 0x2e7 0xc4 0x1c4 0x1c4 0x331 0x2e9 0xc5 0x1c5 0x1c5 0x337 0x2ea 0xc6 0x1c6 0x1c6 0x33d 0x2ec 0xc7 0x1c7 0x1c7 0x343 0x2ed 0xc8 0x1c8 0x1c8 0x349 0x2ef 0xc9 0x1c9 0x1c9 0x34f 0x2f1 0xca 0x1ca 0x1ca 0x355 0x2f2 0xcb 0x1cb 0x1cb 0x35b 0x2f4 0xcc 0x1cc 0x1cc 0x361 0x2f5 0xcd 0x1cd 0x1cd 0x367 0x2f7 0xce 0x1ce 0x1ce 0x36d 0x2f9 0xcf 0x1cf 0x1cf 0x373 0x2fb 0xd0 0x1d0 0x1d0 0x379 0x2fc 0xd1 0x1d1 0x1d1 0x37f 0x2fe 0xd2 0x1d2 0x1d2 0x385 0x2ff 0xd3 0x1d3 0x1d3 0x38b 0x301 0xd4 0x1d4 0x1d4 0x391 0x303 0xd5 0x1d5 0x1d5 0x397 0x304 0xd6 0x1d6 0x1d6 0x39d 0x306 0xd7 0x1d7 0x1d7 0x3a3 0x307 0xd8 0x1d8 0x1d8 0x3a9 0x309 0xd9 0x1d9 0x1d9 0x3af 0x30b 0xda 0x1da 0x1da 0x3b5 0x30d 0xdb 0x1db 0x1db 0x3bb 0x30e 0xdc 0x1dc 0x1dc 0x3c1 0x310 0xdd 0x1dd 0x1dd 0x3c7 0x311 0xde 0x1de 0x1de 0x3cd 0x313 0xdf 0x1df 0x1df 0x3d3 0x315 0xe0 0x1e0 0x1e0 0x3d9 0x316 0xe1 0x1e1 0x1e1 0x3df 0x318 0xe2 0x1e2 0x1e2 0x3e5 0x319 0xe3 0x1e3 0x1e3 0x3eb 0x31b 0xe4 0x1e4 0x1e4 0x3f1 0x31d 0xe5 0x1e5 0x1e5 0x3f7 0x31f 0xe6 0x1e6 0x1e6 0x3ff 0x320>;
		samsung,hbm_candela_map_table_revI = <0x00 0x100 0x100 0x00 0x1a9 0x01 0x101 0x101 0x02 0x1aa 0x02 0x102 0x102 0x04 0x1ac 0x03 0x103 0x103 0x06 0x1ae 0x04 0x104 0x104 0x08 0x1b0 0x05 0x105 0x105 0x0a 0x1b1 0x06 0x106 0x106 0x0c 0x1b3 0x07 0x107 0x107 0x0e 0x1b4 0x08 0x108 0x108 0x10 0x1b6 0x09 0x109 0x109 0x12 0x1b8 0x0a 0x10a 0x10a 0x14 0x1b9 0x0b 0x10b 0x10b 0x16 0x1bb 0x0c 0x10c 0x10c 0x18 0x1bc 0x0d 0x10d 0x10d 0x1a 0x1be 0x0e 0x10e 0x10e 0x1c 0x1c0 0x0f 0x10f 0x10f 0x1e 0x1c2 0x10 0x110 0x110 0x20 0x1c3 0x11 0x111 0x111 0x22 0x1c5 0x12 0x112 0x112 0x24 0x1c6 0x13 0x113 0x113 0x25 0x1c8 0x14 0x114 0x114 0x26 0x1ca 0x15 0x115 0x115 0x27 0x1cb 0x16 0x116 0x116 0x28 0x1cd 0x17 0x117 0x117 0x29 0x1ce 0x18 0x118 0x118 0x2a 0x1d0 0x19 0x119 0x119 0x2b 0x1d2 0x1a 0x11a 0x11a 0x2c 0x1d4 0x1b 0x11b 0x11b 0x2d 0x1d5 0x1c 0x11c 0x11c 0x2e 0x1d7 0x1d 0x11d 0x11d 0x2f 0x1d8 0x1e 0x11e 0x11e 0x30 0x1da 0x1f 0x11f 0x11f 0x31 0x1dc 0x20 0x120 0x120 0x32 0x1dd 0x21 0x121 0x121 0x33 0x1df 0x22 0x122 0x122 0x34 0x1e0 0x23 0x123 0x123 0x35 0x1e2 0x24 0x124 0x124 0x36 0x1e4 0x25 0x125 0x125 0x37 0x1e5 0x26 0x126 0x126 0x38 0x1e7 0x27 0x127 0x127 0x39 0x1e8 0x28 0x128 0x128 0x3a 0x1ea 0x29 0x129 0x129 0x3b 0x1ec 0x2a 0x12a 0x12a 0x3c 0x1ee 0x2b 0x12b 0x12b 0x3d 0x1ef 0x2c 0x12c 0x12c 0x3e 0x1f1 0x2d 0x12d 0x12d 0x3f 0x1f2 0x2e 0x12e 0x12e 0x40 0x1f4 0x2f 0x12f 0x12f 0x41 0x1f6 0x30 0x130 0x130 0x42 0x1f7 0x31 0x131 0x131 0x43 0x1f9 0x32 0x132 0x132 0x44 0x1fa 0x33 0x133 0x133 0x45 0x1fc 0x34 0x134 0x134 0x46 0x1fe 0x35 0x135 0x135 0x47 0x200 0x36 0x136 0x136 0x48 0x201 0x37 0x137 0x137 0x49 0x203 0x38 0x138 0x138 0x4a 0x204 0x39 0x139 0x139 0x4b 0x206 0x3a 0x13a 0x13a 0x4c 0x208 0x3b 0x13b 0x13b 0x4d 0x209 0x3c 0x13c 0x13c 0x4e 0x20b 0x3d 0x13d 0x13d 0x4f 0x20c 0x3e 0x13e 0x13e 0x50 0x20e 0x3f 0x13f 0x13f 0x51 0x210 0x40 0x140 0x140 0x52 0x211 0x41 0x141 0x141 0x53 0x213 0x42 0x142 0x142 0x54 0x215 0x43 0x143 0x143 0x55 0x216 0x44 0x144 0x144 0x56 0x218 0x45 0x145 0x145 0x57 0x21a 0x46 0x146 0x146 0x58 0x21b 0x47 0x147 0x147 0x59 0x21d 0x48 0x148 0x148 0x5a 0x21e 0x49 0x149 0x149 0x5b 0x220 0x4a 0x14a 0x14a 0x5c 0x222 0x4b 0x14b 0x14b 0x5d 0x223 0x4c 0x14c 0x14c 0x5f 0x225 0x4d 0x14d 0x14d 0x61 0x226 0x4e 0x14e 0x14e 0x63 0x228 0x4f 0x14f 0x14f 0x65 0x22a 0x50 0x150 0x150 0x67 0x22b 0x51 0x151 0x151 0x69 0x22d 0x52 0x152 0x152 0x6b 0x22f 0x53 0x153 0x153 0x6d 0x230 0x54 0x154 0x154 0x6f 0x232 0x55 0x155 0x155 0x71 0x234 0x56 0x156 0x156 0x73 0x235 0x57 0x157 0x157 0x75 0x237 0x58 0x158 0x158 0x77 0x238 0x59 0x159 0x159 0x79 0x23a 0x5a 0x15a 0x15a 0x7b 0x23c 0x5b 0x15b 0x15b 0x7d 0x23d 0x5c 0x15c 0x15c 0x7f 0x23f 0x5d 0x15d 0x15d 0x81 0x241 0x5e 0x15e 0x15e 0x83 0x242 0x5f 0x15f 0x15f 0x85 0x244 0x60 0x160 0x160 0x87 0x246 0x61 0x161 0x161 0x89 0x247 0x62 0x162 0x162 0x8b 0x249 0x63 0x163 0x163 0x8d 0x24a 0x64 0x164 0x164 0x8f 0x24c 0x65 0x165 0x165 0x91 0x24e 0x66 0x166 0x166 0x93 0x24f 0x67 0x167 0x167 0x95 0x251 0x68 0x168 0x168 0x97 0x253 0x69 0x169 0x169 0x9a 0x254 0x6a 0x16a 0x16a 0x9d 0x256 0x6b 0x16b 0x16b 0xa0 0x257 0x6c 0x16c 0x16c 0xa3 0x259 0x6d 0x16d 0x16d 0xa6 0x25b 0x6e 0x16e 0x16e 0xa8 0x25c 0x6f 0x16f 0x16f 0xab 0x25e 0x70 0x170 0x170 0xae 0x260 0x71 0x171 0x171 0xb1 0x261 0x72 0x172 0x172 0xb4 0x263 0x73 0x173 0x173 0xb7 0x264 0x74 0x174 0x174 0xba 0x266 0x75 0x175 0x175 0xbd 0x268 0x76 0x176 0x176 0xc0 0x269 0x77 0x177 0x177 0xc3 0x26b 0x78 0x178 0x178 0xc6 0x26d 0x79 0x179 0x179 0xc9 0x26e 0x7a 0x17a 0x17a 0xcc 0x270 0x7b 0x17b 0x17b 0xcf 0x272 0x7c 0x17c 0x17c 0xd2 0x273 0x7d 0x17d 0x17d 0xd5 0x275 0x7e 0x17e 0x17e 0xd8 0x276 0x7f 0x17f 0x17f 0xdb 0x278 0x80 0x180 0x180 0xde 0x27a 0x81 0x181 0x181 0xe1 0x27b 0x82 0x182 0x182 0xe4 0x27d 0x83 0x183 0x183 0xe7 0x27f 0x84 0x184 0x184 0xea 0x280 0x85 0x185 0x185 0xed 0x282 0x86 0x186 0x186 0xf0 0x283 0x87 0x187 0x187 0xf3 0x285 0x88 0x188 0x188 0xf6 0x287 0x89 0x189 0x189 0xf9 0x288 0x8a 0x18a 0x18a 0xfc 0x28a 0x8b 0x18b 0x18b 0xff 0x28c 0x8c 0x18c 0x18c 0x102 0x28d 0x8d 0x18d 0x18d 0x105 0x28f 0x8e 0x18e 0x18e 0x108 0x291 0x8f 0x18f 0x18f 0x10b 0x292 0x90 0x190 0x190 0x10e 0x294 0x91 0x191 0x191 0x111 0x295 0x92 0x192 0x192 0x114 0x297 0x93 0x193 0x193 0x117 0x299 0x94 0x194 0x194 0x11a 0x29a 0x95 0x195 0x195 0x11d 0x29c 0x96 0x196 0x196 0x120 0x29e 0x97 0x197 0x197 0x123 0x29f 0x98 0x198 0x198 0x126 0x2a1 0x99 0x199 0x199 0x129 0x2a3 0x9a 0x19a 0x19a 0x12c 0x2a4 0x9b 0x19b 0x19b 0x12f 0x2a6 0x9c 0x19c 0x19c 0x132 0x2a7 0x9d 0x19d 0x19d 0x135 0x2a9 0x9e 0x19e 0x19e 0x138 0x2ab 0x9f 0x19f 0x19f 0x13b 0x2ac 0xa0 0x1a0 0x1a0 0x13e 0x2ae 0xa1 0x1a1 0x1a1 0x141 0x2af 0xa2 0x1a2 0x1a2 0x144 0x2b1 0xa3 0x1a3 0x1a3 0x147 0x2b3 0xa4 0x1a4 0x1a4 0x14a 0x2b4 0xa5 0x1a5 0x1a5 0x14d 0x2b6 0xa6 0x1a6 0x1a6 0x150 0x2b8 0xa7 0x1a7 0x1a7 0x153 0x2b9 0xa8 0x1a8 0x1a8 0x156 0x2bb 0xa9 0x1a9 0x1a9 0x159 0x2bd 0xaa 0x1aa 0x1aa 0x15c 0x2be 0xab 0x1ab 0x1ab 0x15f 0x2c0 0xac 0x1ac 0x1ac 0x162 0x2c1 0xad 0x1ad 0x1ad 0x165 0x2c3 0xae 0x1ae 0x1ae 0x168 0x2c5 0xaf 0x1af 0x1af 0x16b 0x2c6 0xb0 0x1b0 0x1b0 0x16e 0x2c8 0xb1 0x1b1 0x1b1 0x171 0x2c9 0xb2 0x1b2 0x1b2 0x174 0x2cb 0xb3 0x1b3 0x1b3 0x177 0x2cd 0xb4 0x1b4 0x1b4 0x17a 0x2cf 0xb5 0x1b5 0x1b5 0x17d 0x2d0 0xb6 0x1b6 0x1b6 0x180 0x2d2 0xb7 0x1b7 0x1b7 0x183 0x2d3 0xb8 0x1b8 0x1b8 0x186 0x2d5 0xb9 0x1b9 0x1b9 0x189 0x2d7 0xba 0x1ba 0x1ba 0x18c 0x2d8 0xbb 0x1bb 0x1bb 0x18f 0x2da 0xbc 0x1bc 0x1bc 0x192 0x2db 0xbd 0x1bd 0x1bd 0x195 0x2dd 0xbe 0x1be 0x1be 0x198 0x2df 0xbf 0x1bf 0x1bf 0x19b 0x2e1 0xc0 0x1c0 0x1c0 0x19e 0x2e2 0xc1 0x1c1 0x1c1 0x1a1 0x2e4 0xc2 0x1c2 0x1c2 0x1a4 0x2e5 0xc3 0x1c3 0x1c3 0x1a7 0x2e7 0xc4 0x1c4 0x1c4 0x1aa 0x2e9 0xc5 0x1c5 0x1c5 0x1ad 0x2ea 0xc6 0x1c6 0x1c6 0x1b0 0x2ec 0xc7 0x1c7 0x1c7 0x1b3 0x2ed 0xc8 0x1c8 0x1c8 0x1b6 0x2ef 0xc9 0x1c9 0x1c9 0x1b9 0x2f1 0xca 0x1ca 0x1ca 0x1bc 0x2f2 0xcb 0x1cb 0x1cb 0x1bf 0x2f4 0xcc 0x1cc 0x1cc 0x1c2 0x2f5 0xcd 0x1cd 0x1cd 0x1c5 0x2f7 0xce 0x1ce 0x1ce 0x1c8 0x2f9 0xcf 0x1cf 0x1cf 0x1cb 0x2fb 0xd0 0x1d0 0x1d0 0x1ce 0x2fc 0xd1 0x1d1 0x1d1 0x1d1 0x2fe 0xd2 0x1d2 0x1d2 0x1d4 0x2ff 0xd3 0x1d3 0x1d3 0x1d7 0x301 0xd4 0x1d4 0x1d4 0x1da 0x303 0xd5 0x1d5 0x1d5 0x1dd 0x304 0xd6 0x1d6 0x1d6 0x1e0 0x306 0xd7 0x1d7 0x1d7 0x1e3 0x307 0xd8 0x1d8 0x1d8 0x1e6 0x309 0xd9 0x1d9 0x1d9 0x1e9 0x30b 0xda 0x1da 0x1da 0x1ec 0x30d 0xdb 0x1db 0x1db 0x1ef 0x30e 0xdc 0x1dc 0x1dc 0x1f2 0x310 0xdd 0x1dd 0x1dd 0x1f5 0x311 0xde 0x1de 0x1de 0x1f8 0x313 0xdf 0x1df 0x1df 0x1fb 0x315 0xe0 0x1e0 0x1e0 0x1fe 0x316 0xe1 0x1e1 0x1e1 0x201 0x318 0xe2 0x1e2 0x1e2 0x204 0x319 0xe3 0x1e3 0x1e3 0x207 0x31b 0xe4 0x1e4 0x1e4 0x20a 0x31d 0xe5 0x1e5 0x1e5 0x20d 0x31f 0xe6 0x1e6 0x1e6 0x210 0x320>;
		samsung,candela_map_table_revA = <0x00 0x00 0x00 0x02 0x02 0x01 0x01 0x01 0x03 0x02 0x02 0x02 0x02 0x04 0x03 0x03 0x03 0x03 0x05 0x03 0x04 0x04 0x04 0x07 0x04 0x05 0x05 0x05 0x08 0x05 0x06 0x06 0x06 0x0a 0x05 0x07 0x07 0x07 0x0c 0x06 0x08 0x08 0x08 0x0d 0x07 0x09 0x09 0x09 0x0f 0x07 0x0a 0x0a 0x0a 0x11 0x08 0x0b 0x0b 0x0b 0x13 0x09 0x0c 0x0c 0x0c 0x15 0x0a 0x0d 0x0d 0x0d 0x18 0x0b 0x0e 0x0e 0x0e 0x1a 0x0c 0x0f 0x0f 0x0f 0x1c 0x0d 0x10 0x10 0x10 0x1e 0x0d 0x11 0x11 0x11 0x20 0x0e 0x12 0x12 0x12 0x23 0x0f 0x13 0x13 0x13 0x25 0x10 0x14 0x14 0x14 0x28 0x11 0x15 0x15 0x15 0x2a 0x12 0x16 0x16 0x16 0x2d 0x13 0x17 0x17 0x17 0x2f 0x14 0x18 0x18 0x18 0x32 0x15 0x19 0x19 0x19 0x34 0x16 0x1a 0x1a 0x1a 0x37 0x17 0x1b 0x1b 0x1b 0x3a 0x19 0x1c 0x1c 0x1c 0x3c 0x1a 0x1d 0x1d 0x1d 0x3f 0x1b 0x1e 0x1e 0x1e 0x42 0x1c 0x1f 0x1f 0x1f 0x45 0x1d 0x20 0x20 0x20 0x47 0x1e 0x21 0x21 0x21 0x4a 0x1f 0x22 0x22 0x22 0x4d 0x20 0x23 0x23 0x23 0x50 0x22 0x24 0x24 0x24 0x53 0x23 0x25 0x25 0x25 0x56 0x24 0x26 0x26 0x26 0x59 0x25 0x27 0x27 0x27 0x5c 0x26 0x28 0x28 0x28 0x5f 0x28 0x29 0x29 0x29 0x62 0x29 0x2a 0x2a 0x2a 0x65 0x2a 0x2b 0x2b 0x2b 0x68 0x2b 0x2c 0x2c 0x2c 0x6b 0x2d 0x2d 0x2d 0x2d 0x6e 0x2e 0x2e 0x2e 0x2e 0x71 0x2f 0x2f 0x2f 0x2f 0x74 0x30 0x30 0x30 0x30 0x77 0x32 0x31 0x31 0x31 0x7b 0x33 0x32 0x32 0x32 0x7e 0x34 0x33 0x33 0x33 0x81 0x36 0x34 0x34 0x34 0x84 0x37 0x35 0x35 0x35 0x88 0x38 0x36 0x36 0x36 0x8b 0x3a 0x37 0x37 0x37 0x8e 0x3b 0x38 0x38 0x38 0x92 0x3c 0x39 0x39 0x39 0x95 0x3e 0x3a 0x3a 0x3a 0x98 0x3f 0x3b 0x3b 0x3b 0x9c 0x40 0x3c 0x3c 0x3c 0x9f 0x42 0x3d 0x3d 0x3d 0xa2 0x43 0x3e 0x3e 0x3e 0xa6 0x44 0x3f 0x3f 0x3f 0xa9 0x46 0x40 0x40 0x40 0xad 0x47 0x41 0x41 0x41 0xb0 0x49 0x42 0x42 0x42 0xb4 0x4a 0x43 0x43 0x43 0xb7 0x4c 0x44 0x44 0x44 0xbb 0x4d 0x45 0x45 0x45 0xbe 0x4e 0x46 0x46 0x46 0xc2 0x50 0x47 0x47 0x47 0xc5 0x51 0x48 0x48 0x48 0xc9 0x53 0x49 0x49 0x49 0xcd 0x54 0x4a 0x4a 0x4a 0xd0 0x56 0x4b 0x4b 0x4b 0xd4 0x57 0x4c 0x4c 0x4c 0xd7 0x59 0x4d 0x4d 0x4d 0xdb 0x5a 0x4e 0x4e 0x4e 0xdf 0x5c 0x4f 0x4f 0x4f 0xe3 0x5d 0x50 0x50 0x50 0xe6 0x5f 0x51 0x51 0x51 0xea 0x60 0x52 0x52 0x52 0xee 0x62 0x53 0x53 0x53 0xf1 0x63 0x54 0x54 0x54 0xf5 0x65 0x55 0x55 0x55 0xf9 0x66 0x56 0x56 0x56 0xfd 0x68 0x57 0x57 0x57 0x101 0x69 0x58 0x58 0x58 0x104 0x6b 0x59 0x59 0x59 0x108 0x6c 0x5a 0x5a 0x5a 0x10c 0x6e 0x5b 0x5b 0x5b 0x110 0x70 0x5c 0x5c 0x5c 0x114 0x71 0x5d 0x5d 0x5d 0x118 0x73 0x5e 0x5e 0x5e 0x11b 0x74 0x5f 0x5f 0x5f 0x11f 0x76 0x60 0x60 0x60 0x123 0x77 0x61 0x61 0x61 0x127 0x79 0x62 0x62 0x62 0x12b 0x7b 0x63 0x63 0x63 0x12f 0x7c 0x64 0x64 0x64 0x133 0x7e 0x65 0x65 0x65 0x137 0x7f 0x66 0x66 0x66 0x13b 0x81 0x67 0x67 0x67 0x13f 0x83 0x68 0x68 0x68 0x143 0x84 0x69 0x69 0x69 0x147 0x86 0x6a 0x6a 0x6a 0x14b 0x88 0x6b 0x6b 0x6b 0x14f 0x89 0x6c 0x6c 0x6c 0x153 0x8b 0x6d 0x6d 0x6d 0x157 0x8c 0x6e 0x6e 0x6e 0x15b 0x8e 0x6f 0x6f 0x6f 0x15f 0x90 0x70 0x70 0x70 0x163 0x91 0x71 0x71 0x71 0x168 0x93 0x72 0x72 0x72 0x16c 0x95 0x73 0x73 0x73 0x170 0x96 0x74 0x74 0x74 0x174 0x98 0x75 0x75 0x75 0x178 0x9a 0x76 0x76 0x76 0x17c 0x9c 0x77 0x77 0x77 0x180 0x9d 0x78 0x78 0x78 0x185 0x9f 0x79 0x79 0x79 0x189 0xa1 0x7a 0x7a 0x7a 0x18d 0xa2 0x7b 0x7b 0x7b 0x191 0xa4 0x7c 0x7c 0x7c 0x195 0xa6 0x7d 0x7d 0x7d 0x19a 0xa7 0x7e 0x7e 0x7e 0x19e 0xa9 0x7f 0x7f 0x7f 0x1a2 0xab 0x80 0x80 0x80 0x1a6 0xad 0x81 0x81 0x81 0x1ab 0xae 0x82 0x82 0x82 0x1af 0xb0 0x83 0x83 0x83 0x1b3 0xb2 0x84 0x84 0x84 0x1b8 0xb4 0x85 0x85 0x85 0x1bc 0xb5 0x86 0x86 0x86 0x1c0 0xb7 0x87 0x87 0x87 0x1c5 0xb9 0x88 0x88 0x88 0x1c9 0xbb 0x89 0x89 0x89 0x1cd 0xbc 0x8a 0x8a 0x8a 0x1d1 0xbe 0x8b 0x8b 0x8b 0x1d6 0xc0 0x8c 0x8c 0x8c 0x1da 0xc2 0x8d 0x8d 0x8d 0x1de 0xc3 0x8e 0x8e 0x8e 0x1e3 0xc5 0x8f 0x8f 0x8f 0x1e7 0xc7 0x90 0x90 0x90 0x1eb 0xc9 0x91 0x91 0x91 0x1f0 0xcb 0x92 0x92 0x92 0x1f4 0xcc 0x93 0x93 0x93 0x1f8 0xce 0x94 0x94 0x94 0x1fd 0xd0 0x95 0x95 0x95 0x201 0xd2 0x96 0x96 0x96 0x206 0xd4 0x97 0x97 0x97 0x20a 0xd6 0x98 0x98 0x98 0x20e 0xd7 0x99 0x99 0x99 0x213 0xd9 0x9a 0x9a 0x9a 0x217 0xdb 0x9b 0x9b 0x9b 0x21c 0xdd 0x9c 0x9c 0x9c 0x220 0xdf 0x9d 0x9d 0x9d 0x225 0xe1 0x9e 0x9e 0x9e 0x229 0xe2 0x9f 0x9f 0x9f 0x22e 0xe4 0xa0 0xa0 0xa0 0x232 0xe6 0xa1 0xa1 0xa1 0x237 0xe8 0xa2 0xa2 0xa2 0x23b 0xea 0xa3 0xa3 0xa3 0x240 0xec 0xa4 0xa4 0xa4 0x244 0xed 0xa5 0xa5 0xa5 0x249 0xef 0xa6 0xa6 0xa6 0x24d 0xf1 0xa7 0xa7 0xa7 0x252 0xf3 0xa8 0xa8 0xa8 0x256 0xf5 0xa9 0xa9 0xa9 0x25b 0xf7 0xaa 0xaa 0xaa 0x260 0xf9 0xab 0xab 0xab 0x264 0xfb 0xac 0xac 0xac 0x269 0xfd 0xad 0xad 0xad 0x26d 0xfe 0xae 0xae 0xae 0x272 0x100 0xaf 0xaf 0xaf 0x277 0x102 0xb0 0xb0 0xb0 0x27b 0x104 0xb1 0xb1 0xb1 0x280 0x106 0xb2 0xb2 0xb2 0x284 0x108 0xb3 0xb3 0xb3 0x289 0x10a 0xb4 0xb4 0xb4 0x28e 0x10c 0xb5 0xb5 0xb5 0x292 0x10e 0xb6 0xb6 0xb6 0x297 0x110 0xb7 0xb7 0xb7 0x29c 0x112 0xb8 0xb8 0xb8 0x2a0 0x113 0xb9 0xb9 0xb9 0x2a5 0x115 0xba 0xba 0xba 0x2aa 0x117 0xbb 0xbb 0xbb 0x2ae 0x119 0xbc 0xbc 0xbc 0x2b3 0x11b 0xbd 0xbd 0xbd 0x2b8 0x11d 0xbe 0xbe 0xbe 0x2bd 0x11f 0xbf 0xbf 0xbf 0x2c1 0x121 0xc0 0xc0 0xc0 0x2c6 0x123 0xc1 0xc1 0xc1 0x2cb 0x125 0xc2 0xc2 0xc2 0x2d0 0x127 0xc3 0xc3 0xc3 0x2d4 0x129 0xc4 0xc4 0xc4 0x2d9 0x12b 0xc5 0xc5 0xc5 0x2de 0x12d 0xc6 0xc6 0xc6 0x2e3 0x12f 0xc7 0xc7 0xc7 0x2e8 0x131 0xc8 0xc8 0xc8 0x2ec 0x133 0xc9 0xc9 0xc9 0x2f1 0x135 0xca 0xca 0xca 0x2f6 0x137 0xcb 0xcb 0xcb 0x2fb 0x139 0xcc 0xcc 0xcc 0x300 0x13b 0xcd 0xcd 0xcd 0x304 0x13d 0xce 0xce 0xce 0x309 0x13f 0xcf 0xcf 0xcf 0x30e 0x141 0xd0 0xd0 0xd0 0x313 0x143 0xd1 0xd1 0xd1 0x318 0x145 0xd2 0xd2 0xd2 0x31d 0x147 0xd3 0xd3 0xd3 0x322 0x149 0xd4 0xd4 0xd4 0x327 0x14b 0xd5 0xd5 0xd5 0x32b 0x14d 0xd6 0xd6 0xd6 0x330 0x14f 0xd7 0xd7 0xd7 0x335 0x151 0xd8 0xd8 0xd8 0x33a 0x153 0xd9 0xd9 0xd9 0x33f 0x155 0xda 0xda 0xda 0x344 0x157 0xdb 0xdb 0xdb 0x349 0x159 0xdc 0xdc 0xdc 0x34e 0x15b 0xdd 0xdd 0xdd 0x353 0x15d 0xde 0xde 0xde 0x358 0x15f 0xdf 0xdf 0xdf 0x35d 0x161 0xe0 0xe0 0xe0 0x362 0x163 0xe1 0xe1 0xe1 0x367 0x165 0xe2 0xe2 0xe2 0x36c 0x167 0xe3 0xe3 0xe3 0x371 0x169 0xe4 0xe4 0xe4 0x376 0x16b 0xe5 0xe5 0xe5 0x37b 0x16d 0xe6 0xe6 0xe6 0x380 0x170 0xe7 0xe7 0xe7 0x385 0x172 0xe8 0xe8 0xe8 0x38a 0x174 0xe9 0xe9 0xe9 0x38f 0x176 0xea 0xea 0xea 0x394 0x178 0xeb 0xeb 0xeb 0x399 0x17a 0xec 0xec 0xec 0x39e 0x17c 0xed 0xed 0xed 0x3a3 0x17e 0xee 0xee 0xee 0x3a8 0x180 0xef 0xef 0xef 0x3ad 0x182 0xf0 0xf0 0xf0 0x3b2 0x184 0xf1 0xf1 0xf1 0x3b7 0x186 0xf2 0xf2 0xf2 0x3bc 0x189 0xf3 0xf3 0xf3 0x3c1 0x18b 0xf4 0xf4 0xf4 0x3c7 0x18d 0xf5 0xf5 0xf5 0x3cc 0x18f 0xf6 0xf6 0xf6 0x3d1 0x191 0xf7 0xf7 0xf7 0x3d6 0x193 0xf8 0xf8 0xf8 0x3db 0x195 0xf9 0xf9 0xf9 0x3e0 0x197 0xfa 0xfa 0xfa 0x3e5 0x199 0xfb 0xfb 0xfb 0x3ea 0x19b 0xfc 0xfc 0xfc 0x3f0 0x19e 0xfd 0xfd 0xfd 0x3f5 0x1a0 0xfe 0xfe 0xfe 0x3fa 0x1a2 0xff 0xff 0xff 0x3ff 0x1a4>;
		samsung,mtp_read_sysfs_rx_cmds_revA = [06 01 00 00 00 00 01 00 00 00 00];
		samsung,ddi_id_rx_cmds_revA = [06 01 00 00 00 00 01 d6 05 00 00];
		samsung,cell_id_rx_cmds_revA = [06 01 00 00 00 00 01 92 10 00 02];
		samsung,octa_id_rx_cmds_revA = [06 01 00 00 00 00 01 a1 04 00 0b];
		samsung,module_info_rx_cmds_revA = [06 01 00 00 00 00 01 a1 0b 00 00];
		samsung,manufacture_id2_rx_cmds_revA = [06 01 00 00 00 00 01 dc 01 00 00];
		samsung,manufacture_id1_rx_cmds_revA = [06 01 00 00 00 00 01 db 01 00 00];
		samsung,manufacture_id0_rx_cmds_revA = [06 01 00 00 00 00 01 da 01 00 00];
		samsung,acl_off_tx_cmds_revA = [29 01 00 00 00 00 02 55 00];
		samsung,acl_on_tx_cmds_revA = [29 00 00 00 00 00 04 b0 03 b3 65 29 00 00 00 00 00 14 65 55 00 b0 51 66 98 15 55 55 55 08 f1 c6 48 40 00 20 10 09 29 00 00 00 00 00 02 55 03];
		samsung,vrr_tx_cmds_revA = [29 00 00 00 00 00 03 60 00 00 29 00 00 00 00 00 04 b0 00 28 68 29 00 00 00 00 00 02 68 02 29 00 00 00 00 00 02 f7 0f];
		samsung,gamma_mode2_hbm_tx_cmds_revA = [29 00 00 00 00 00 04 b0 00 02 90 29 00 00 00 00 00 02 90 14 29 00 00 00 00 00 02 53 e0 29 00 00 00 00 00 03 51 03 ff 29 00 00 00 00 00 02 b5 14 29 00 00 00 00 00 04 b0 00 76 63 29 00 00 00 00 00 04 63 00 00 00];
		samsung,gamma_mode2_hbm_tx_cmds_revG = <0x29000000 0x391 0x2002900 0x00 0x253e029 0x00 0x35103 0xff290000 0x02 0xb5142900 0x00 0x4b00076 0x63290000 0x04 0x63000000>;
		samsung,gamma_mode2_hbm_tx_cmds_revI = <0x29000000 0x4b0 0x916329 0x00 0x26320 0x29000000 0x4b0 0x2036329 0x00 0x363f1 0x290000 0x02 0x53e02900 0x00 0x35103ff 0x29000000 0x2b5 0x14290000 0x04 0xb0020363 0x29000000 0x363 0xf0072900 0x00 0x4b00076 0x63290000 0x04 0x63000000>;
		samsung,gamma_mode2_normal_tx_cmds_revA = [29 00 00 00 00 00 04 b0 00 02 90 29 00 00 00 00 00 02 90 1c 29 00 00 00 00 00 02 53 20 29 00 00 00 00 00 03 51 03 ff 29 00 00 00 00 00 02 b5 14 29 00 00 00 00 00 04 b0 00 76 63 29 00 00 00 00 00 04 63 00 00 00];
		samsung,gamma_mode2_normal_tx_cmds_revG = <0x29000000 0x391 0x2012900 0x00 0x2532029 0x00 0x35103 0xff290000 0x02 0xb5142900 0x00 0x4b00076 0x63290000 0x04 0x63000000>;
		samsung,gamma_mode2_normal_tx_cmds_revI = <0x29000000 0x4b0 0x916329 0x00 0x26360 0x29000000 0x4b0 0x2036329 0x00 0x363f1 0x7290000 0x02 0x53202900 0x00 0x35103ff 0x29000000 0x2b5 0x14290000 0x04 0xb0020363 0x29000000 0x363 0xf0002900 0x00 0x4b00076 0x63290000 0x04 0x63000000>;
		samsung,smooth_dimming_off_tx_cmds_revA = [29 00 00 00 00 00 03 f0 5a 5a 29 00 00 00 00 00 04 b0 00 91 63 29 00 00 00 00 00 02 63 20 29 01 00 00 11 00 02 53 20 29 00 00 00 00 00 02 f7 0f 29 01 00 00 00 00 03 f0 a5 a5];
		samsung,mtp_write_sysfs_tx_cmds_revA = <0x29000000 0x3d00 0x00 0x00 0x00 0x00 0x00 0x00 0x00 0x00 0x00 0x00 0x00 0x00 0x00 0x00 0x00>;
		samsung,reg_read_pos_tx_cmds_revA = [29 00 00 00 00 00 04 b0 00 00 00];
		samsung,display_off_tx_cmds_revA = [05 01 00 00 00 00 02 28 00];
		samsung,display_on_tx_cmds_revA = [29 00 00 00 00 00 03 9f a5 a5 05 00 00 00 00 00 02 29 00 29 01 00 00 00 00 03 9f 5a 5a];
		samsung,brightness_tx_cmds_revA = <0x39010000 0x100 0x39010000 0x100 0x39010000 0x100 0x39010000 0x100 0x39010000 0x100 0x39010000 0x100 0x39010000 0x100 0x39010000 0x100 0x39010000 0x100 0x39010000 0x100 0x39010000 0x100 0x39010000 0x100 0x39010000 0x100 0x39010000 0x100 0x39010000 0x100 0x39010000 0x100 0x39010000 0x100 0x39010000 0x100 0x39010000 0x100 0x39010000 0x100 0x39010000 0x100 0x39010000 0x100 0x39010000 0x100 0x39010000 0x100 0x39010000 0x100 0x39010000 0x100 0x39010000 0x100 0x39010000 0x100 0x39010000 0x100 0x39010000 0x100 0x39010000 0x100 0x39010000 0x100 0x39010000 0x100 0x39010000 0x100 0x39010000 0x100 0x39010000 0x100 0x39010000 0x100 0x39010000 0x100 0x39010000 0x100 0x39010000 0x100 0x39010000 0x100 0x39010000 0x100 0x39010000 0x100 0x39010000 0x100 0x39010000 0x100 0x39010000 0x100 0x39010000 0x100 0x39010000 0x100 0x39010000 0x100 0x39010000 0x100>;
		samsung,level2_key_disable_tx_cmds_revA = [29 01 00 00 00 00 03 fc a5 a5];
		samsung,level2_key_enable_tx_cmds_revA = [29 01 00 00 00 00 03 fc 5a 5a];
		samsung,level1_key_disable_tx_cmds_revA = [29 01 00 00 00 00 03 f0 a5 a5];
		samsung,level1_key_enable_tx_cmds_revA = [29 01 00 00 00 00 03 f0 5a 5a];
		samsung,level0_key_disable_tx_cmds_revA = [29 01 00 00 00 00 03 9f 5a 5a];
		samsung,level0_key_enable_tx_cmds_revA = [29 01 00 00 00 00 03 9f a5 a5];
		ss,self_display = <&self_display_FC3_dtsi>;
		samsung,esd-irq-trigger1 = "falling";
		samsung,support_vrr_based_bl;
		samsung,support-optical-fingerprint;
		samsung,support_factory_panel_swap;
		samsung,rsc_4_frame_idle;
		samsung,two_byte_gpara;
		samsung,pointing_gpara;
		samsung,support_gpara;
		samsung,support_lpm;
		samsung,elvss_interpolation_temperature = <0xfffffff0>;
		samsung,skip_read_on_pre;
		samsung,support_gamma_mode2;
		samsung,disp-model = "AMS646YD01";
		samsung,panel-vendor = "SDC";
		qcom,mdss-dsi-panel-status-check-mode = "irq_check";
		qcom,esd-check-enabled;
		qcom,ulps-enabled;
		qcom,mdss-dsi-tx-eot-append;
		qcom,mdss-dsi-rx-eot-ignore;
		qcom,mdss-dsi-lp11-init;
		qcom,mdss-dsi-reset-sequence = <0x00 0x0a 0x01 0x0a>;
		qcom,mdss-pan-physical-height-dimension = <0x96>;
		qcom,mdss-pan-physical-width-dimension = <0x43>;
		qcom,mdss-dsi-dma-trigger = "trigger_sw";
		qcom,mdss-dsi-mdp-trigger = "none";
		qcom,mdss-dsi-stream = <0x00>;
		qcom,mdss-dsi-t-clk-post = <0x10>;
		qcom,mdss-dsi-t-clk-pre = <0x3e>;
		qcom,mdss-dsi-lane-map = "lane_map_0123";
		qcom,mdss-dsi-lane-3-state;
		qcom,mdss-dsi-lane-2-state;
		qcom,mdss-dsi-lane-1-state;
		qcom,mdss-dsi-lane-0-state;
		qcom,mdss-dsi-color-order = "rgb_swap_rgb";
		qcom,mdss-dsi-virtual-channel-id = <0x00>;
		qcom,mdss-dsi-pixel-packing = "loose";
		qcom,mdss-dsi-wr-mem-continue = <0x3c>;
		qcom,mdss-dsi-wr-mem-start = <0x2c>;
		qcom,mdss-dsi-te-dcs-command = <0x01>;
		qcom,mdss-dsi-te-pin-select = <0x01>;
		qcom,mdss-dsi-panel-type = "dsi_cmd_mode";
		qcom,mdss-brightness-default-level = <0xff>;
		qcom,mdss-brightness-max-level = <0x1e6>;
		qcom,mdss-dsi-bl-max-level = <0x1e6>;
		qcom,mdss-dsi-bl-min-level = <0x01>;
		qcom,mdss-dsi-bl-pmic-control-type = "bl_ctrl_dcs";
		qcom,mdss-dsi-border-color = <0x00>;
		qcom,mdss-dsi-underflow-color = <0xff>;
		qcom,mdss-dsi-bpp = <0x18>;
		label = "ss_dsi_panel_S6E3FC3_AMS646YD01_LO_FHD";
		qcom,mdss-dsi-panel-name = "ss_dsi_panel_S6E3FC3_AMS646YD01_LO_FHD";

		qcom,panel-supply-entries {
			#size-cells = <0x00>;
			#address-cells = <0x01>;

			qcom,panel-supply-entry@1 {
				qcom,supply-pre-off-sleep = <0x02>;
				qcom,supply-post-on-sleep = <0x00>;
				qcom,supply-pre-on-sleep = <0x00>;
				qcom,supply-disable-load = <0x64>;
				qcom,supply-enable-load = <0x186a0>;
				qcom,supply-max-voltage = <0x1b7740>;
				qcom,supply-min-voltage = <0x1b7740>;
				qcom,supply-name = "panel_vddi";
				reg = <0x01>;
			};

			qcom,panel-supply-entry@0 {
				qcom,supply-pre-off-sleep = <0x00>;
				qcom,supply-post-on-sleep = <0x00>;
				qcom,supply-pre-on-sleep = <0x00>;
				qcom,supply-disable-load = <0x64>;
				qcom,supply-enable-load = <0x186a0>;
				qcom,supply-max-voltage = <0x2dc6c0>;
				qcom,supply-min-voltage = <0x2dc6c0>;
				qcom,supply-name = "panel_vci";
				reg = <0x00>;
			};
		};

		qcom,mdss-dsi-display-timings {

			fhd60 {
				qcom,mdss-dsc-block-prediction-enable;
				qcom,mdss-dsc-bit-per-pixel = <0x08>;
				qcom,mdss-pps-delay-ms = <0x00>;
				qcom,mdss-dsc-bit-per-component = <0x08>;
				qcom,mdss-dsc-slice-per-pkt = <0x01>;
				qcom,mdss-dsc-slice-width = <0x21c>;
				qcom,mdss-dsc-slice-height = <0x28>;
				qcom,mdss-dsc-scr-version = <0x00>;
				qcom,mdss-dsc-version = <0x11>;
				qcom,compression-mode = "dsc";
				qcom,panel-roi-alignment = <0x438 0x28 0x438 0x28 0x438 0x28>;
				qcom,mdss-dsi-off-command-state = "dsi_hs_mode";
				qcom,mdss-dsi-on-command-state = "dsi_hs_mode";
				qcom,mdss-dsi-off-command = [29 00 00 00 00 00 03 9f a5 a5 05 01 00 00 14 00 02 28 00 05 01 00 00 78 00 02 10 00 29 01 00 00 00 00 03 9f 5a 5a];
				qcom,mdss-dsi-on-command = [05 01 00 00 1e 00 02 11 00 29 00 00 00 00 00 03 f0 5a 5a 29 00 00 00 00 00 2a f2 00 05 0e 58 54 01 0c 00 04 26 e4 2f b0 0c 09 74 26 e4 0c 00 04 10 00 10 26 a8 10 00 10 10 3c 10 00 40 30 c8 00 c8 00 00 ce 29 00 00 00 00 00 02 35 00 29 00 00 00 00 00 05 2a 00 00 04 37 29 00 00 00 00 00 05 2b 00 00 09 5f 29 00 00 00 00 00 02 e5 15 29 00 00 00 00 00 04 ed 44 4c 20 29 00 00 00 00 00 04 b0 00 04 f2 29 00 00 00 00 00 02 f2 54 29 00 00 00 00 00 03 cc 5c 51 07 01 00 00 00 00 01 01 0a 01 00 00 00 00 59 11 00 00 89 30 80 09 60 04 38 00 28 02 1c 02 1c 02 00 02 0e 00 20 03 dd 00 07 00 0c 02 77 02 8b 18 00 10 f0 03 0c 20 00 06 0b 0b 33 0e 1c 2a 38 46 54 62 69 70 77 79 7b 7d 7e 01 02 01 00 09 40 09 be 19 fc 19 fa 19 f8 1a 38 1a 78 1a b6 2a f6 2b 34 2b 74 3b 74 63 f4 00 29 00 00 00 00 00 04 b0 00 27 f2 29 00 00 00 00 00 02 f2 00 29 00 00 00 00 00 04 b0 00 2e f2 29 00 00 00 00 00 02 f2 55 29 00 00 00 00 00 04 b0 00 92 63 29 00 00 00 00 00 02 63 08 29 00 00 00 00 00 02 f7 0f 29 01 00 00 5a 00 03 f0 a5 a5];
				qcom,mdss-dsi-t-clk-post = <0x1a>;
				qcom,mdss-dsi-t-clk-pre = <0x1f>;
				qcom,mdss-dsi-panel-phy-timings = [00 24 0a 0a 26 24 0a 0a 09 02 04 00 1f 1a];
				qcom,mdss-dsi-panel-clockrate = <0x420abd00>;
				qcom,mdss-mdp-transfer-time-us = <0x3dfa>;
				samsung,mdss-dsi-sot-hs-mode;
				qcom,mdss-dsi-panel-framerate = <0x3c>;
				qcom,mdss-dsi-v-front-porch = <0x10>;
				qcom,mdss-dsi-v-back-porch = <0x02>;
				qcom,mdss-dsi-v-pulse-width = <0x02>;
				qcom,mdss-dsi-h-sync-skew = <0x00>;
				qcom,mdss-dsi-h-front-porch = <0x50>;
				qcom,mdss-dsi-h-back-porch = <0x58>;
				qcom,mdss-dsi-h-pulse-width = <0x54>;
				qcom,mdss-dsi-panel-height = <0x960>;
				qcom,mdss-dsi-panel-width = <0x438>;
				qcom,default-topology-index = <0x00>;
				qcom,display-topology = <0x01 0x01 0x01>;
			};

			fhd120 {
				qcom,mdss-dsc-block-prediction-enable;
				qcom,mdss-dsc-bit-per-pixel = <0x08>;
				qcom,mdss-pps-delay-ms = <0x00>;
				qcom,mdss-dsc-bit-per-component = <0x08>;
				qcom,mdss-dsc-slice-per-pkt = <0x01>;
				qcom,mdss-dsc-slice-width = <0x21c>;
				qcom,mdss-dsc-slice-height = <0x28>;
				qcom,mdss-dsc-scr-version = <0x00>;
				qcom,mdss-dsc-version = <0x11>;
				qcom,compression-mode = "dsc";
				qcom,panel-roi-alignment = <0x438 0x28 0x438 0x28 0x438 0x28>;
				qcom,mdss-dsi-off-command-state = "dsi_hs_mode";
				qcom,mdss-dsi-on-command-state = "dsi_hs_mode";
				qcom,mdss-dsi-off-command = [29 00 00 00 00 00 03 9f a5 a5 05 01 00 00 14 00 02 28 00 05 01 00 00 78 00 02 10 00 29 01 00 00 00 00 03 9f 5a 5a];
				qcom,mdss-dsi-on-command = [05 01 00 00 1e 00 02 11 00 29 00 00 00 00 00 03 f0 5a 5a 29 00 00 00 00 00 2a f2 00 05 0e 58 54 01 0c 00 04 26 e4 2f b0 0c 09 74 26 e4 0c 00 04 10 00 10 26 a8 10 00 10 10 34 10 00 40 30 c8 00 c8 00 00 ce 29 00 00 00 00 00 02 35 00 29 00 00 00 00 00 05 2a 00 00 04 37 29 00 00 00 00 00 05 2b 00 00 09 5f 29 00 00 00 00 00 02 e5 15 29 00 00 00 00 00 04 ed 44 4c 20 29 00 00 00 00 00 04 b0 00 04 f2 29 00 00 00 00 00 02 f2 54 29 00 00 00 00 00 03 cc 5c 51 07 01 00 00 00 00 01 01 0a 01 00 00 00 00 59 11 00 00 89 30 80 09 60 04 38 00 28 02 1c 02 1c 02 00 02 0e 00 20 03 dd 00 07 00 0c 02 77 02 8b 18 00 10 f0 03 0c 20 00 06 0b 0b 33 0e 1c 2a 38 46 54 62 69 70 77 79 7b 7d 7e 01 02 01 00 09 40 09 be 19 fc 19 fa 19 f8 1a 38 1a 78 1a b6 2a f6 2b 34 2b 74 3b 74 63 f4 00 29 00 00 00 00 00 04 b0 00 27 f2 29 00 00 00 00 00 02 f2 00 29 00 00 00 00 00 04 b0 00 2e f2 29 00 00 00 00 00 02 f2 55 29 00 00 00 00 00 04 b0 00 92 63 29 00 00 00 00 00 02 63 08 29 00 00 00 00 00 02 f7 0f 29 01 00 00 5a 00 03 f0 a5 a5];
				qcom,mdss-dsi-t-clk-post = <0x1a>;
				qcom,mdss-dsi-t-clk-pre = <0x1f>;
				qcom,mdss-dsi-panel-phy-timings = [00 24 0a 0a 26 24 0a 0a 09 02 04 00 1f 1a];
				qcom,mdss-dsi-panel-clockrate = <0x420abd00>;
				qcom,mdss-mdp-transfer-time-us = <0x1d6d>;
				samsung,mdss-dsi-sot-hs-mode;
				qcom,mdss-dsi-panel-framerate = <0x78>;
				qcom,mdss-dsi-v-front-porch = <0x0f>;
				qcom,mdss-dsi-v-back-porch = <0x02>;
				qcom,mdss-dsi-v-pulse-width = <0x02>;
				qcom,mdss-dsi-h-sync-skew = <0x00>;
				qcom,mdss-dsi-h-front-porch = <0x50>;
				qcom,mdss-dsi-h-back-porch = <0x58>;
				qcom,mdss-dsi-h-pulse-width = <0x54>;
				qcom,mdss-dsi-panel-height = <0x960>;
				qcom,mdss-dsi-panel-width = <0x438>;
				qcom,default-topology-index = <0x00>;
				qcom,display-topology = <0x01 0x01 0x01>;
			};
		};
	};
};
